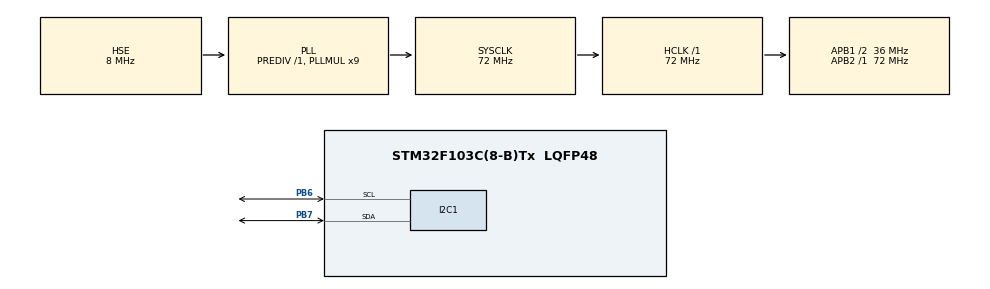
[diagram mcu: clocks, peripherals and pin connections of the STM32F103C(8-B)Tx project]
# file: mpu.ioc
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Mcu.Family=STM32F1
Mcu.Name=STM32F103C(8-B)Tx
Mcu.Package=LQFP48
NVIC.PriorityGroup=NVIC_PRIORITYGROUP_4
PB6.Mode=I2C
PB6.Signal=I2C1_SCL
PB7.Mode=I2C
PB7.Signal=I2C1_SDA
PD0-OSC_IN.Mode=HSE-External-Oscillator
PD0-OSC_IN.Signal=RCC_OSC_IN
PD1-OSC_OUT.Mode=HSE-External-Oscillator
PD1-OSC_OUT.Signal=RCC_OSC_OUT
ProjectManager.HeapSize=0x200
ProjectManager.StackSize=0x400
ProjectManager.TargetToolchain=STM32CubeIDE
RCC.AHBFreq_Value=72000000
RCC.APB1CLKDivider=RCC_HCLK_DIV2
RCC.APB1Freq_Value=36000000
RCC.APB1TimFreq_Value=72000000
RCC.APB2Freq_Value=72000000
RCC.APB2TimFreq_Value=72000000
RCC.HCLKFreq_Value=72000000
RCC.PLLMUL=RCC_PLL_MUL9
RCC.PLLSourceVirtual=RCC_PLLSOURCE_HSE
RCC.SYSCLKFreq_VALUE=72000000
RCC.SYSCLKSource=RCC_SYSCLKSOURCE_PLLCLK
RCC.USBFreq_Value=72000000
board=custom

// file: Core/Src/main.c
/* USER CODE BEGIN Header */
/**
  ******************************************************************************
  * @file           : main.c
  * @brief          : Main program body
  ******************************************************************************
  * @attention
  *
  * Copyright (c) 2026 STMicroelectronics.
  * All rights reserved.
  *
  * This software is licensed under terms that can be found in the LICENSE file
  * in the root directory of this software component.
  * If no LICENSE file comes with this software, it is provided AS-IS.
  *
  ******************************************************************************
  */
/* USER CODE END Header */
#include "main.h"

/* USER CODE BEGIN PD */
#define MPU6050_ADDR   (0x68 << 1)  // HAL wants 8-bit address
#define PWR_MGMT_1     0x6B
#define SMPLRT_DIV     0x19
#define CONFIG_REG     0x1A
#define GYRO_CONFIG    0x1B
#define ACCEL_CONFIG   0x1C
#define WHO_AM_I       0x75
#define ACCEL_XOUT_H   0x3B
/* USER CODE END PD */

I2C_HandleTypeDef hi2c1;
DMA_HandleTypeDef hdma_i2c1_rx;
DMA_HandleTypeDef hdma_i2c1_tx;

/* USER CODE BEGIN PV */
int16_t mpu_buf[6];
int a=101;
HAL_StatusTypeDef m;
HAL_StatusTypeDef n;
HAL_StatusTypeDef b;
HAL_StatusTypeDef v;
HAL_StatusTypeDef x;

/* USER CODE END PV */

void SystemClock_Config(void);
static void MX_GPIO_Init(void);
static void MX_DMA_Init(void);
static void MX_I2C1_Init(void);

/* USER CODE BEGIN 0 */
void MPU6050_ReadAll(I2C_HandleTypeDef *hi2c, int16_t *ax, int16_t *ay, int16_t *az,
                      int16_t *gx, int16_t *gy, int16_t *gz,HAL_StatusTypeDef * x) {
    uint8_t buf[14];
    *x=HAL_I2C_Mem_Read(hi2c, MPU6050_ADDR, ACCEL_XOUT_H, 1, buf, 14, 100);

    *ax = (int16_t)(buf[0]  << 8 | buf[1]);
    *ay = (int16_t)(buf[2]  << 8 | buf[3]);
    *az = (int16_t)(buf[4]  << 8 | buf[5]);
    // buf[6],buf[7] = temperature, skip or parse separately
    *gx = (int16_t)(buf[8]  << 8 | buf[9]);
    *gy = (int16_t)(buf[10] << 8 | buf[11]);
    *gz = (int16_t)(buf[12] << 8 | buf[13]);
}

void MPU6050_Init(I2C_HandleTypeDef *hi2c) {
    uint8_t check, data;

    // Verify device is alive — should read 0x68
    HAL_I2C_Mem_Read(hi2c, MPU6050_ADDR, WHO_AM_I, 1, &check, 1, 100);

    if (check == 0x68) {
        // Wake up: clear sleep bit, select internal 8MHz clock
        data = 0x00;
        HAL_I2C_Mem_Write(hi2c, MPU6050_ADDR, PWR_MGMT_1, 1, &data, 1, 100);

        // Sample rate divider: 1kHz / (1 + 7) = 125Hz
        data = 0x07;
        HAL_I2C_Mem_Write(hi2c, MPU6050_ADDR, SMPLRT_DIV, 1, &data, 1, 100);

        // Accel config: ±2g
        data = 0x00;
        HAL_I2C_Mem_Write(hi2c, MPU6050_ADDR, ACCEL_CONFIG, 1, &data, 1, 100);

        // Gyro config: ±250°/s
        data = 0x00;
        HAL_I2C_Mem_Write(hi2c, MPU6050_ADDR, GYRO_CONFIG, 1, &data, 1, 100);
    }
     else
     {
        a=60;
     }

}
/* USER CODE END 0 */

int main(void)
{

  /* USER CODE BEGIN 1 */
	uint8_t check, data;
  /* USER CODE END 1 */

  /* MCU Configuration--------------------------------------------------------*/

  /* Reset of all peripherals, Initializes the Flash interface and the Systick. */
  HAL_Init();

  /* Configure the system clock */
  SystemClock_Config();

  /* Initialize all configured peripherals */
  MX_GPIO_Init();
  MX_DMA_Init();
  MX_I2C1_Init();
  /* USER CODE BEGIN 2 */
//MPU6050_Init(&hi2c1);
  /* USER CODE END 2 */

  /* Infinite loop */
  while (1)
  {
	  /*HAL_I2C_Mem_Read(&hi2c1, MPU6050_ADDR, WHO_AM_I, 1, &check, 1, 100);

	      if (check == 0x68) {
	          // Wake up: clear sleep bit, select internal 8MHz clock
	          data = 0x00;
	          m=HAL_I2C_Mem_Write(&hi2c1, MPU6050_ADDR, PWR_MGMT_1, 1, &data, 1, 100);

	          // Sample rate divider: 1kHz / (1 + 7) = 125Hz
	          data = 0x07;
	          n=HAL_I2C_Mem_Write(&hi2c1, MPU6050_ADDR, SMPLRT_DIV, 1, &data, 1, 100);

	          // Accel config: ±2g
	          data = 0x00;
	          v=HAL_I2C_Mem_Write(&hi2c1, MPU6050_ADDR, ACCEL_CONFIG, 1, &data, 1, 100);

	          // Gyro config: ±250°/s
	          data = 0x00;
	          b=HAL_I2C_Mem_Write(&hi2c1, MPU6050_ADDR, GYRO_CONFIG, 1, &data, 1, 100);
	      }
	       else
	       {
	          a=60;
	       }*/
	  MPU6050_ReadAll(&hi2c1,&mpu_buf[0],&mpu_buf[1],&mpu_buf[2],&mpu_buf[3],&mpu_buf[4],&mpu_buf[5],&x);
	  HAL_Delay(1);
  }
}

void SystemClock_Config(void)
{
  RCC_OscInitTypeDef RCC_OscInitStruct = {0};
  RCC_ClkInitTypeDef RCC_ClkInitStruct = {0};

  /** Initializes the RCC Oscillators according to the specified parameters
  * in the RCC_OscInitTypeDef structure.
  */
  RCC_OscInitStruct.OscillatorType = RCC_OSCILLATORTYPE_HSE;
  RCC_OscInitStruct.HSEState = RCC_HSE_ON;
  RCC_OscInitStruct.HSEPredivValue = RCC_HSE_PREDIV_DIV1;
  RCC_OscInitStruct.HSIState = RCC_HSI_ON;
  RCC_OscInitStruct.PLL.PLLState = RCC_PLL_ON;
  RCC_OscInitStruct.PLL.PLLSource = RCC_PLLSOURCE_HSE;
  RCC_OscInitStruct.PLL.PLLMUL = RCC_PLL_MUL9;
  if (HAL_RCC_OscConfig(&RCC_OscInitStruct) != HAL_OK)
  {
    Error_Handler();
  }

  /** Initializes the CPU, AHB and APB buses clocks
  */
  RCC_ClkInitStruct.ClockType = RCC_CLOCKTYPE_HCLK|RCC_CLOCKTYPE_SYSCLK
                              |RCC_CLOCKTYPE_PCLK1|RCC_CLOCKTYPE_PCLK2;
  RCC_ClkInitStruct.SYSCLKSource = RCC_SYSCLKSOURCE_PLLCLK;
  RCC_ClkInitStruct.AHBCLKDivider = RCC_SYSCLK_DIV1;
  RCC_ClkInitStruct.APB1CLKDivider = RCC_HCLK_DIV2;
  RCC_ClkInitStruct.APB2CLKDivider = RCC_HCLK_DIV1;

  if (HAL_RCC_ClockConfig(&RCC_ClkInitStruct, FLASH_LATENCY_2) != HAL_OK)
  {
    Error_Handler();
  }
}

static void MX_I2C1_Init(void)
{

  hi2c1.Instance = I2C1;
  hi2c1.Init.ClockSpeed = 100000;
  hi2c1.Init.DutyCycle = I2C_DUTYCYCLE_2;
  hi2c1.Init.OwnAddress1 = 0;
  hi2c1.Init.AddressingMode = I2C_ADDRESSINGMODE_7BIT;
  hi2c1.Init.DualAddressMode = I2C_DUALADDRESS_DISABLE;
  hi2c1.Init.OwnAddress2 = 0;
  hi2c1.Init.GeneralCallMode = I2C_GENERALCALL_DISABLE;
  hi2c1.Init.NoStretchMode = I2C_NOSTRETCH_DISABLE;
  if (HAL_I2C_Init(&hi2c1) != HAL_OK)
  {
    Error_Handler();
  }

}

static void MX_DMA_Init(void)
{

  /* DMA controller clock enable */
  __HAL_RCC_DMA1_CLK_ENABLE();

  /* DMA interrupt init */
  /* DMA1_Channel6_IRQn interrupt configuration */
  HAL_NVIC_SetPriority(DMA1_Channel6_IRQn, 0, 0);
  HAL_NVIC_EnableIRQ(DMA1_Channel6_IRQn);
  /* DMA1_Channel7_IRQn interrupt configuration */
  HAL_NVIC_SetPriority(DMA1_Channel7_IRQn, 0, 0);
  HAL_NVIC_EnableIRQ(DMA1_Channel7_IRQn);

}

static void MX_GPIO_Init(void)
{

  /* GPIO Ports Clock Enable */
  __HAL_RCC_GPIOD_CLK_ENABLE();
  __HAL_RCC_GPIOB_CLK_ENABLE();

}

void Error_Handler(void)
{
  __disable_irq();
  while (1)
  {
  }
}
